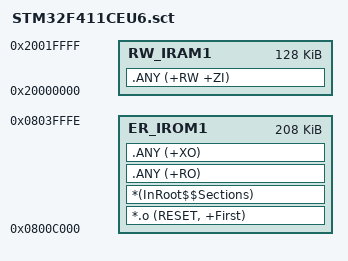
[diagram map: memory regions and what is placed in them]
; *************************************************************
; *** Scatter-Loading Description File generated by uVision ***
; *************************************************************

LR_IROM1 0x0800C000 0x00033FFF  {    ; 加载域
  ER_IROM1 0x0800C000 0x00033FFF  {  ; 执行域
   *.o (RESET, +First)			     ; 1. 中断向量表 - 必须放在最前面！ 
   *(InRoot$$Sections)				 ; 2. 库相关的重要段
   .ANY (+RO)						 ; 3. 其他的只读数据和代码
   .ANY (+XO)						 ; 4. 其他的可执行代码
  }
  
  RW_IRAM1 0x20000000 0x00020000  {  ; RAM域
   .ANY (+RW +ZI)					 ; 所有的读写数据
  }
}

